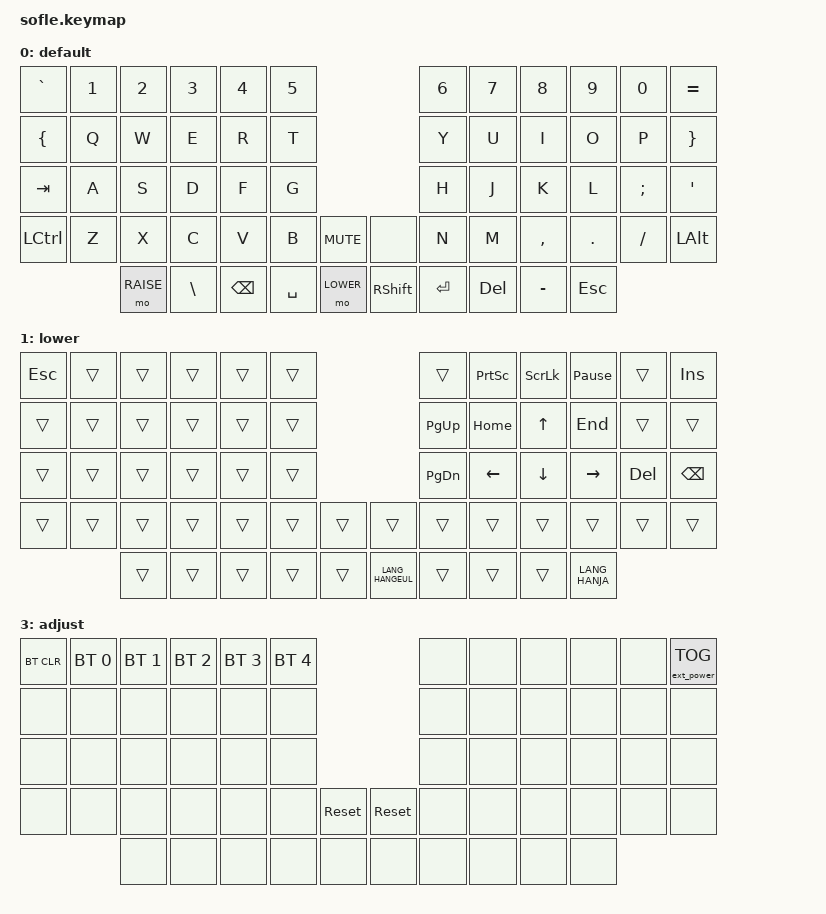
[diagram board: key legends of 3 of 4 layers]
/*
 * Copyright (c) 2020 The ZMK Contributors
 *
 * SPDX-License-Identifier: MIT
 */

#include <behaviors.dtsi>
#include <dt-bindings/zmk/keys.h>
#include <dt-bindings/zmk/bt.h>
#include <dt-bindings/zmk/rgb.h>
#include <dt-bindings/zmk/ext_power.h>

#define BASE 0
#define LOWER 1
#define RAISE 2
#define ADJUST 3

/ {

   // Activate ADJUST layer by pressing raise and lower
    conditional_layers {
        compatible = "zmk,conditional-layers";
        adjust_layer {
            if-layers = <LOWER RAISE>;
            then-layer = <ADJUST>;
        };
    };

    keymap {
        compatible = "zmk,keymap";

        default_layer {
            display-name = "default";
// ------------------------------------------------------------------------------------------------------------
// |   `   |  1  |   2    |   3    |   4    |   5    |                       |   6    |   7    |   8    |  9    |   0    |   =   |
// |  {    |  Q  |   W    |   E    |   R    |   T    |                       |   Y    |   U    |   I    |  O    |   P    |   }   |
// | TAB   |  A  |   S    |   D    |   F    |   G    |                       |   H    |   J    |   K    |  L    |   ;    |   '   |
// | SHIFT |  Z  |   X    |   C    |   V    |   B    |   MUTE   |  |         |   N    |   M    |   ,    |  .    |   /    | SHIFT |
//               | LOWER  |   \    |  ALT   |  BKSPC |   SPACE  |  |  ENTER  |  DEL   |  CTRL  |   -    | RAISE |
            bindings = <
&kp GRAVE &kp N1 &kp N2    &kp N3   &kp N4    &kp N5                          &kp N6    &kp N7    &kp N8      &kp N9    &kp N0   &kp EQUAL
&kp LBRC  &kp Q  &kp W     &kp E    &kp R     &kp T                           &kp Y     &kp U     &kp I       &kp O     &kp P    &kp RBRC
&kp TAB   &kp A  &kp S     &kp D    &kp F     &kp G                           &kp H     &kp J     &kp K       &kp L     &kp SEMI &kp SQT
&kp LCTRL &kp Z  &kp X     &kp C    &kp V     &kp B     &kp C_MUTE  &none     &kp N     &kp M     &kp COMMA   &kp DOT   &kp FSLH &kp LALT
                 &mo RAISE &kp BSLH &kp BSPC  &kp SPACE &mo LOWER   &kp RSHFT &kp RET   &kp DEL   &kp MINUS   &kp ESC
            >;

            sensor-bindings = <&inc_dec_kp C_VOL_UP C_VOL_DN &inc_dec_kp PG_UP PG_DN>;
        };

        lower_layer {
            display-name = "lower";
// TODO: Some binds are waiting for shifted keycode support.
// ------------------------------------------------------------------------------------------------------------
// |  ESC  |     |       |        |        |        |                               |          |  PSCRN |   SLCK | PAUSE   |        |   INS  |
// |       |     |       |        |        |        |                               |  PGUP    |   HOME |    ^   |  END    |        |        |
// |       |     |       |        |        |        |                               |  PGDN    |   <-   |    v   |  ->     |   DEL  |  BKSPC |
// |       |     |       |        |        |        |             | |               |          |        |        |         |        |        |
//               |       |        |        |        |  HANJA      | | HANGEUL       |  MENU    |        |        |         |
            bindings = <
&kp ESC  &trans   &trans   &trans   &trans   &trans                                   &trans       &kp PSCRN  &kp SLCK   &kp PAUSE_BREAK  &trans  &kp INS
&trans   &trans   &trans   &trans   &trans   &trans                                   &kp PG_UP    &kp HOME   &kp UP     &kp END          &trans  &trans
&trans   &trans   &trans   &trans   &trans   &trans                                   &kp PG_DN    &kp LEFT   &kp DOWN   &kp RIGHT        &kp DEL &kp BSPC
&trans   &trans   &trans   &trans   &trans   &trans   &trans         &trans           &trans       &trans     &trans     &trans           &trans  &trans
                  &trans   &trans   &trans   &trans   &trans         &kp LANG_HANGEUL &trans       &trans     &trans     &kp LANG_HANJA
            >;

            sensor-bindings = <&inc_dec_kp C_VOL_UP C_VOL_DN &inc_dec_kp PG_UP PG_DN>;
        };

        raise_layer {
            display-name = "raise";
// ------------------------------------------------------------------------------------------------------------
// |  F11  |   F1      |   F2     |  F3      |  F4      |   F5      |                     |    F6  |   F7   |    F8  |   F9    |   F10    |   F12   |
// |       |           |          |          |          |           |                     |        |   N7   |    N8  |   N9    |  SLASH   |   STAR  |
// |  CAPS |           |          |          |          |           |                     |  LNLCK |   N4   |    N5  |   N6    |  MINUS   |   PLUS  |
// |       |  UNDO     |  CUT     | COPY     | PASTE    |           |        |  |         |    N0  |   N1   |    N2  |   N3    |    .     |         |
//                     |          |          |          |   LGUI    |        |  |         |        |        |        |         | 
            bindings = <
&kp F11    &kp F1      &kp F2      &kp F3      &kp F4       &kp F5                        &kp F6     &kp F7    &kp F8    &kp F9   &kp F10    &kp F12
&trans     &trans      &trans      &trans      &trans       &trans                        &trans     &kp N7    &kp N8    &kp N9   &kp SLASH  &kp STAR
&kp CLCK   &trans      &trans      &trans      &trans       &trans                        &kp LNLCK  &kp N4    &kp N5    &kp N6   &kp MINUS  &kp PLUS
&trans     &kp K_UNDO  &kp K_CUT   &kp K_COPY  &kp K_PASTE  &trans   &trans   &trans      &kp N0     &kp N1    &kp N2    &kp N3   &kp DOT    &trans
                       &trans      &trans      &trans       &trans   &trans   &kp K_CMENU &kp LGUI   &trans    &trans    &trans   &trans
            >;

            sensor-bindings = <&inc_dec_kp C_VOL_UP C_VOL_DN &inc_dec_kp PG_UP PG_DN>;
        };

        adjust_layer {
// ----------------------------------------------------------------------------------------------------------------------------
// | BTCLR |  BT1      |  BT2       |   BT3     |   BT4      |   BT5     |                       |     |     |     |     |     | EXTPWR |
// |       |           |            |           |            |           |                       |     |     |     |     |     |        |
// |       |           |            |           |            |           |                       |     |     |     |     |     |        |
// |       |           |            |           |            |           |         |  |          |     |     |     |     |     |        |
//                     |            |           |            |           |         |  |          |     |     |     |     |
            display-name = "adjust";
            bindings = <
&bt BT_CLR &bt BT_SEL 0 &bt BT_SEL 1 &bt BT_SEL 2 &bt BT_SEL 3 &bt BT_SEL 4                       &none &none &none &none &none &ext_power EP_TOG
&none       &none        &none        &none        &none        &none                             &none &none &none &none &none &none
&none       &none        &none        &none        &none        &none                             &none &none &none &none &none &none
&none       &none        &none        &none        &none        &none     &sys_reset  &sys_reset  &none &none &none &none &none &none
                         &none        &none        &none        &none     &none       &none       &none &none &none &none
            >;
        };

    };
};
